VERSION ""

NS_ :

BS_:

BU_:

BO_ 512 RPi: 2 Vector__XXX
 SG_ RPiBattery_Internal_Resistance : 0|12@1+ (1E-05,0) [0|0.04095] "" Vector__XXX

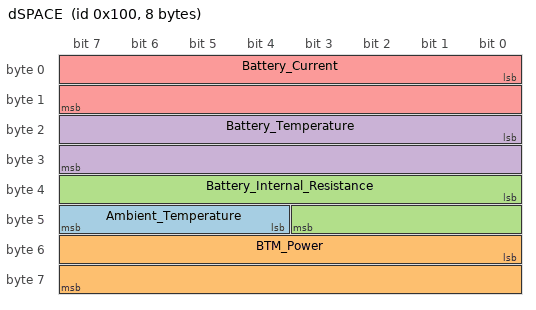
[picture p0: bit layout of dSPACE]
BO_ 256 dSPACE: 8 Vector__XXX
 SG_ Ambient_Temperature : 44|4@1+ (1,287) [287|302] "" Vector__XXX
 SG_ BTM_Power : 48|16@1- (0.1,0) [-3276.8|3276.7] "" Vector__XXX
 SG_ Battery_Internal_Resistance : 32|12@1+ (1E-05,0) [0|0.04095] "" Vector__XXX
 SG_ Battery_Temperature : 16|16@1+ (0.001,270) [270|335.535] "" Vector__XXX
 SG_ Battery_Current : 0|16@1- (0.01,0) [-327.68|327.67] "" Vector__XXX

BA_DEF_ SG_  "GenSigSendType" ENUM  "Cyclic","OnWrite","OnWriteWithRepetition","OnChange","OnChangeWithRepetition","IfActive","IfActiveWithRepetition","NoSigSendType";
BA_DEF_ BO_  "GenMsgSendType " ENUM  "Cyclic","not_used","not_used","not_used","not_used","Cyclic","not_used","IfActive","NoMsgSendType";
BA_DEF_  "DBName" STRING ;
BA_DEF_ BO_  "GenMsgCycleTime" INT 2 50000;
BA_DEF_ BO_  "GenMsgDelayTime" INT 1 1000;
BA_DEF_ BO_  "GenMsgNrOfRepetitions" INT 1 999999;
BA_DEF_ BO_  "GenMsgSendType" ENUM  "cyclic","spontaneous","cyclicIfActive","spontaneousWithDelay","cyclicAndSpontaneous","cyclicAndSpontaneousWithDelay","spontaneousWithRepetition","cyclicIfActiveAndSpontaneousWD";
BA_DEF_ SG_  "GenSigStartValue" FLOAT 0 100000000000;
BA_DEF_DEF_  "GenSigSendType" "Cyclic";
BA_DEF_DEF_  "GenMsgSendType " "NoMsgSendType";
BA_DEF_DEF_  "DBName" "";
BA_DEF_DEF_  "GenMsgCycleTime" 100;
BA_DEF_DEF_  "GenMsgDelayTime" 1;
BA_DEF_DEF_  "GenMsgNrOfRepetitions" 1;
BA_DEF_DEF_  "GenMsgSendType" "spontaneous";
BA_DEF_DEF_  "GenSigStartValue" 0;
BA_ "DBName" "dt_can";
BA_ "GenSigStartValue" SG_ 256 Ambient_Temperature 8;
BA_ "GenSigStartValue" SG_ 256 Battery_Temperature 25000;
